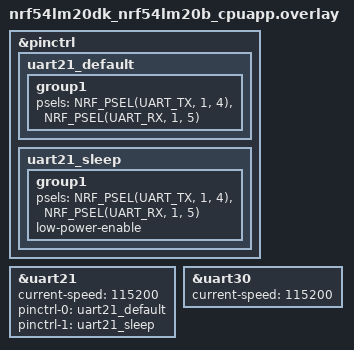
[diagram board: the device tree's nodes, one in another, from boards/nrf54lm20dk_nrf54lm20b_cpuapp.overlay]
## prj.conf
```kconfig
#
# Copyright (c) 2026 Nordic Semiconductor ASA
#
# SPDX-License-Identifier: LicenseRef-Nordic-5-Clause
#

# Logging and console
CONFIG_LOG=y
CONFIG_CONSOLE=y
CONFIG_SERIAL=y
CONFIG_ASSERT=y
CONFIG_LOG_DEFAULT_LEVEL=3

#new: interrupt driven uart for uart_game
CONFIG_UART_INTERRUPT_DRIVEN=y

# GPIO for the temporary sw0 test-score button.
CONFIG_GPIO=y

# Keep printk off the deferred-log path so the forwarded "Command: X" line is
# emitted synchronously (matches the game_controller convention for its
# serial game-controller protocol).
CONFIG_LOG_PRINTK=n

# Bluetooth: central role, connects to the game_controller peripheral and
# subscribes to its Nordic UART Service (NUS) notifications.
CONFIG_BT=y
CONFIG_BT_CENTRAL=y
CONFIG_BT_GATT_CLIENT=y
CONFIG_BT_DEVICE_NAME="Game Receiver"

# One peripheral is held: "Game Controller". The peer table in
# src/ble/ble_central.c BUILD_ASSERTs against this, so raising the number of
# peers there without raising this fails the build rather than silently
# refusing the link.
CONFIG_BT_MAX_CONN=1

CONFIG_BT_GATT_DM=y
CONFIG_BT_NUS_CLIENT=y

# Peripherals are matched by advertised name rather than by a hardcoded address,
# so a board can be swapped without reflashing this one. One filter slot per
# expected peer.
CONFIG_BT_SCAN=y
CONFIG_BT_SCAN_FILTER_ENABLE=y
CONFIG_BT_SCAN_NAME_CNT=1
```

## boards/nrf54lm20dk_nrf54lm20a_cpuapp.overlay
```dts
/*
 * Copyright (c) 2026 Nordic Semiconductor ASA
 * SPDX-License-Identifier: LicenseRef-Nordic-5-Clause
 */

/* Dedicated UART link to the hub's nRF9151, which publishes the highscore
 * over MQTT. Kept separate from the console UART so controller-command
 * forwarding on the console is unaffected. Default uart30 pins on this DK are
 * TX P0.6 / RX P0.7; cross TX<->RX to the nRF9151 and share a ground wire.
 */
&uart30 {
	status = "okay";
	current-speed = <115200>;
};
```

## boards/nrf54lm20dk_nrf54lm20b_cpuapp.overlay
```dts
/*
 * Copyright (c) 2026 Nordic Semiconductor ASA
 * SPDX-License-Identifier: LicenseRef-Nordic-5-Clause
 */

/*
 * UART roles on this board:
 *   uart20 -> VCOM0: console / debug logging (board default pins, untouched).
 *   uart30 -> VCOM1: game-control link to the PC. Scores come in on it and the
 *             relayed controller commands go out on it (P0.6 TX / P0.7 RX).
 *   uart21 -> dedicated 2-wire link to the hub's nRF9151, on expansion-header
 *             pins TX P1.04 / RX P1.05. Cross TX<->RX to the nRF9151 uart1
 *             (its RX is P0.28) and share a ground wire.
 */

&pinctrl {
	uart21_default: uart21_default {
		group1 {
			psels = <NRF_PSEL(UART_TX, 1, 4)>,
				<NRF_PSEL(UART_RX, 1, 5)>;
		};
	};

	uart21_sleep: uart21_sleep {
		group1 {
			psels = <NRF_PSEL(UART_TX, 1, 4)>,
				<NRF_PSEL(UART_RX, 1, 5)>;
			low-power-enable;
		};
	};
};

&uart21 {
	status = "okay";
	current-speed = <115200>;
	pinctrl-0 = <&uart21_default>;
	pinctrl-1 = <&uart21_sleep>;
	pinctrl-names = "default", "sleep";
};

&uart30 {
	status = "okay";
	current-speed = <115200>;
};
```

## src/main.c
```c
/*
 * Copyright (c) 2026 Nordic Semiconductor ASA
 *
 * SPDX-License-Identifier: LicenseRef-Nordic-5-Clause
 *
 * @brief Game receiver entry point.
 *
 * Bridges the game_controller's BLE commands onto this board's game-control
 * link (VCOM1, uart30): connects as a NUS central and relays every received
 * token as a "Command: <token>" line, keeping the console (VCOM0) for debug
 * logging.
 */

#include <zephyr/kernel.h>
#include <zephyr/logging/log.h>

#include "ble/ble_central.h"
#include "led_status/led_status.h"
#include "score_bridge/score_bridge.h"
#include "test_button/test_button.h"

LOG_MODULE_REGISTER(main);

int main(void)
{
	int err;

	/* Before the BLE central, so the LED is already blinking by the time
	 * scanning starts and the board never looks dead at boot.
	 *
	 * A failure here is not fatal: relaying commands is this board's job, and
	 * losing the indicator is no reason to stop doing it. led_status_*() calls
	 * from the BLE callbacks become no-ops.
	 */
	err = led_status_init();
	if (err) {
		LOG_WRN("Status LED init failed (err %d); continuing without LEDs", err);
	}

	err = score_bridge_init();
	if (err) {
		LOG_ERR("Score bridge init failed (err %d)", err);
		return err;
	}



	/* TEMPORARY: sw0 sends a test score until the game console can. */
	err = test_button_init();
	if (err) {
		LOG_ERR("Test button init failed (err %d)", err);
		return err;
	}

	err = ble_central_init();
	if (err) {
		LOG_ERR("BLE central init failed (err %d)", err);
		return err;
	}

	return 0;
}
```
